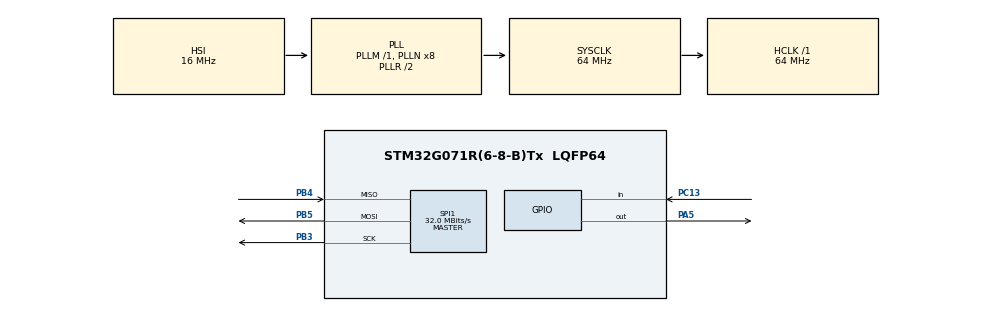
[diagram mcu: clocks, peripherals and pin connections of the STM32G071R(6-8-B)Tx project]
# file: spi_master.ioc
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Mcu.Family=STM32G0
Mcu.Name=STM32G071R(6-8-B)Tx
Mcu.Package=LQFP64
PA5.Signal=GPIO_Output
PB3.Mode=Full_Duplex_Master
PB3.Signal=SPI1_SCK
PB4.Mode=Full_Duplex_Master
PB4.Signal=SPI1_MISO
PB5.Mode=Full_Duplex_Master
PB5.Signal=SPI1_MOSI
PC13.Signal=GPIO_Input
ProjectManager.HeapSize=0x200
ProjectManager.StackSize=0x400
ProjectManager.TargetToolchain=MDK-ARM V5.27
RCC.ADCFreq_Value=64000000
RCC.AHBFreq_Value=64000000
RCC.CortexFreq_Value=64000000
RCC.EXTERNAL_CLOCK_VALUE=48000
RCC.HCLKFreq_Value=64000000
RCC.HSE_VALUE=8000000
RCC.HSI_VALUE=16000000
RCC.LSE_VALUE=32768
RCC.SYSCLKFreq_VALUE=64000000
RCC.SYSCLKSource=RCC_SYSCLKSOURCE_PLLCLK
RCC.VCOOutputFreq_Value=128000000
SPI1.CalculateBaudRate=32.0 MBits/s
SPI1.DataSize=SPI_DATASIZE_8BIT
SPI1.Direction=SPI_DIRECTION_2LINES
SPI1.Mode=SPI_MODE_MASTER
SPI1.VirtualType=VM_MASTER
VP_SYS_VS_DBSignals.Mode=DisableDeadBatterySignals
board=custom

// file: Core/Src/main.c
/* USER CODE BEGIN Header */
/**
  ******************************************************************************
  * @file           : main.c
  * @brief          : Main program body
  ******************************************************************************
  * @attention
  *
  * <h2><center>&copy; Copyright (c) 2021 STMicroelectronics.
  * All rights reserved.</center></h2>
  *
  * This software component is licensed by ST under BSD 3-Clause license,
  * the "License"; You may not use this file except in compliance with the
  * License. You may obtain a copy of the License at:
  *                        opensource.org/licenses/BSD-3-Clause
  *
  ******************************************************************************
  */
/* USER CODE END Header */
#include "main.h"

SPI_HandleTypeDef hspi1;

uint8_t TxMessage[3]={1,2,3};
uint8_t RxMessage[3];

void SystemClock_Config(void);
static void MX_GPIO_Init(void);
static void MX_SPI1_Init(void);
/* USER CODE BEGIN PFP */
static uint16_t Buffercmp(uint8_t *pBuffer1, uint8_t *pBuffer2, uint16_t BufferLength);
/* USER CODE END PFP */

int main(void)
{

  /* MCU Configuration--------------------------------------------------------*/

  /* Reset of all peripherals, Initializes the Flash interface and the Systick. */
  HAL_Init();

  /* Configure the system clock */
  SystemClock_Config();

  /* Initialize all configured peripherals */
  MX_GPIO_Init();
  MX_SPI1_Init();
  /* USER CODE BEGIN 2 */
 while(HAL_GPIO_ReadPin(GPIOC,GPIO_PIN_13)==1){HAL_GPIO_TogglePin(GPIOA,GPIO_PIN_5);HAL_Delay(200);}

 switch (HAL_SPI_TransmitReceive(&hspi1, (uint8_t *)TxMessage, (uint8_t *)RxMessage, 3, 5000))
  {
    case HAL_OK:
      /* Communication is completed ___________________________________________ */
      /* Compare the sent and received buffers */
      if (Buffercmp((uint8_t *)TxMessage, (uint8_t *)TxMessage, 3))
      {
        /* Transfer error in transmission process */
        Error_Handler();
      }
      /* Turn LED4 on: Transfer in transmission/Reception process is correct */
   HAL_GPIO_WritePin(GPIOA,GPIO_PIN_5,GPIO_PIN_SET);
      break;

    case HAL_TIMEOUT:
    /* An Error Occur ______________________________________________________ */
    case HAL_ERROR:
      /* Call Timeout Handler */
      Error_Handler();
      break;
    default:
      break;
  }
  /* USER CODE END 2 */

  /* Infinite loop */
  while (1)
  {

  }
}

void SystemClock_Config(void)
{
  RCC_OscInitTypeDef RCC_OscInitStruct = {0};
  RCC_ClkInitTypeDef RCC_ClkInitStruct = {0};

  /** Configure the main internal regulator output voltage
  */
  HAL_PWREx_ControlVoltageScaling(PWR_REGULATOR_VOLTAGE_SCALE1);
  /** Initializes the RCC Oscillators according to the specified parameters
  * in the RCC_OscInitTypeDef structure.
  */
  RCC_OscInitStruct.OscillatorType = RCC_OSCILLATORTYPE_HSI;
  RCC_OscInitStruct.HSIState = RCC_HSI_ON;
  RCC_OscInitStruct.HSIDiv = RCC_HSI_DIV1;
  RCC_OscInitStruct.HSICalibrationValue = RCC_HSICALIBRATION_DEFAULT;
  RCC_OscInitStruct.PLL.PLLState = RCC_PLL_ON;
  RCC_OscInitStruct.PLL.PLLSource = RCC_PLLSOURCE_HSI;
  RCC_OscInitStruct.PLL.PLLM = RCC_PLLM_DIV1;
  RCC_OscInitStruct.PLL.PLLN = 8;
  RCC_OscInitStruct.PLL.PLLP = RCC_PLLP_DIV2;
  RCC_OscInitStruct.PLL.PLLQ = RCC_PLLQ_DIV2;
  RCC_OscInitStruct.PLL.PLLR = RCC_PLLR_DIV2;
  if (HAL_RCC_OscConfig(&RCC_OscInitStruct) != HAL_OK)
  {
    Error_Handler();
  }
  /** Initializes the CPU, AHB and APB buses clocks
  */
  RCC_ClkInitStruct.ClockType = RCC_CLOCKTYPE_HCLK|RCC_CLOCKTYPE_SYSCLK
                              |RCC_CLOCKTYPE_PCLK1;
  RCC_ClkInitStruct.SYSCLKSource = RCC_SYSCLKSOURCE_PLLCLK;
  RCC_ClkInitStruct.AHBCLKDivider = RCC_SYSCLK_DIV1;
  RCC_ClkInitStruct.APB1CLKDivider = RCC_HCLK_DIV1;

  if (HAL_RCC_ClockConfig(&RCC_ClkInitStruct, FLASH_LATENCY_2) != HAL_OK)
  {
    Error_Handler();
  }
}

static void MX_SPI1_Init(void)
{

  /* SPI1 parameter configuration*/
  hspi1.Instance = SPI1;
  hspi1.Init.Mode = SPI_MODE_MASTER;
  hspi1.Init.Direction = SPI_DIRECTION_2LINES;
  hspi1.Init.DataSize = SPI_DATASIZE_8BIT;
  hspi1.Init.CLKPolarity = SPI_POLARITY_LOW;
  hspi1.Init.CLKPhase = SPI_PHASE_1EDGE;
  hspi1.Init.NSS = SPI_NSS_SOFT;
  hspi1.Init.BaudRatePrescaler = SPI_BAUDRATEPRESCALER_2;
  hspi1.Init.FirstBit = SPI_FIRSTBIT_MSB;
  hspi1.Init.TIMode = SPI_TIMODE_DISABLE;
  hspi1.Init.CRCCalculation = SPI_CRCCALCULATION_DISABLE;
  hspi1.Init.CRCPolynomial = 7;
  hspi1.Init.CRCLength = SPI_CRC_LENGTH_DATASIZE;
  hspi1.Init.NSSPMode = SPI_NSS_PULSE_ENABLE;
  if (HAL_SPI_Init(&hspi1) != HAL_OK)
  {
    Error_Handler();
  }

}

static void MX_GPIO_Init(void)
{
  GPIO_InitTypeDef GPIO_InitStruct = {0};

  /* GPIO Ports Clock Enable */
  __HAL_RCC_GPIOC_CLK_ENABLE();
  __HAL_RCC_GPIOA_CLK_ENABLE();
  __HAL_RCC_GPIOB_CLK_ENABLE();

  /*Configure GPIO pin Output Level */
  HAL_GPIO_WritePin(GPIOA, GPIO_PIN_5, GPIO_PIN_RESET);

  /*Configure GPIO pin : PC13 */
  GPIO_InitStruct.Pin = GPIO_PIN_13;
  GPIO_InitStruct.Mode = GPIO_MODE_INPUT;
  GPIO_InitStruct.Pull = GPIO_NOPULL;
  HAL_GPIO_Init(GPIOC, &GPIO_InitStruct);

  /*Configure GPIO pin : PA5 */
  GPIO_InitStruct.Pin = GPIO_PIN_5;
  GPIO_InitStruct.Mode = GPIO_MODE_OUTPUT_PP;
  GPIO_InitStruct.Pull = GPIO_NOPULL;
  GPIO_InitStruct.Speed = GPIO_SPEED_FREQ_LOW;
  HAL_GPIO_Init(GPIOA, &GPIO_InitStruct);

}

static uint16_t Buffercmp(uint8_t *pBuffer1, uint8_t *pBuffer2, uint16_t BufferLength)
{
  while (BufferLength--)
  {
    if ((*pBuffer1) != *pBuffer2)
    {
      return BufferLength;
    }
    pBuffer1++;
    pBuffer2++;
  }

  return 0;
}
void Error_Handler(void)
{
  __disable_irq();
  while (1)
  {
  }
}

/************************ (C) COPYRIGHT STMicroelectronics *****END OF FILE****/
